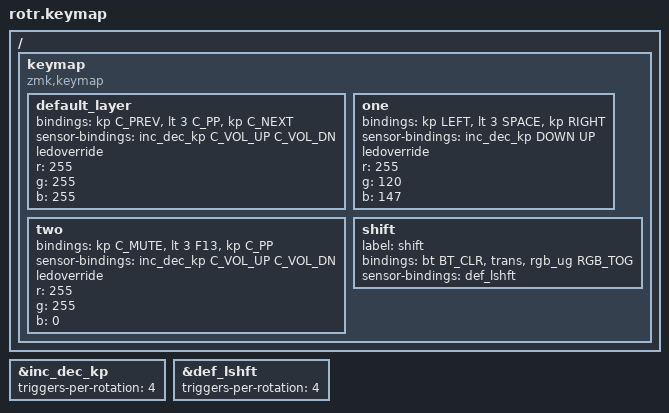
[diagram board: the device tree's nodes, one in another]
#include <behaviors.dtsi>
#include <dt-bindings/zmk/keys.h>
#include <dt-bindings/zmk/rgb.h>
#include <dt-bindings/zmk/bt.h>

&inc_dec_kp {
	triggers-per-rotation = <4>;
};
&def_lshft {
	triggers-per-rotation = <4>;
};

/ {
	keymap {
		compatible = "zmk,keymap";

		default_layer {
			//PREV | PLAY/PAUSE | NEXT -- VOL UP | VOL DN
			bindings = <&kp C_PREV &lt 3 C_PP &kp C_NEXT>;
			sensor-bindings = <&inc_dec_kp C_VOL_UP C_VOL_DN>;
			ledoverride;
			r = <255>;
			g = <255>;
			b = <255>;
		};
		one {
			//LEFT | SPACE | RIGHT -- UP | DOWN
			bindings = <&kp LEFT &lt 3 SPACE &kp RIGHT>;
			sensor-bindings = <&inc_dec_kp DOWN UP>;
			ledoverride;
			r = <255>;
			g = <120>;
			b = <147>;
		};
		two {
			//MUTE | F13 | PLAY/PAUSE -- VOL UP | VOL DN
			bindings = <&kp C_MUTE &lt 3 F13 &kp C_PP>;
			sensor-bindings = <&inc_dec_kp C_VOL_UP C_VOL_DN>;
			ledoverride;
			r = <255>;
			g = <255>;
			b = <0>;
		};
		shift {
			label = "shift";
			//BLUETOOTH | ___ | RGB TOGGLE | LAYER SHIFT
			bindings = <&bt BT_CLR &trans &rgb_ug RGB_TOG>;
			sensor-bindings = <&def_lshft>;
		};
	};
};
